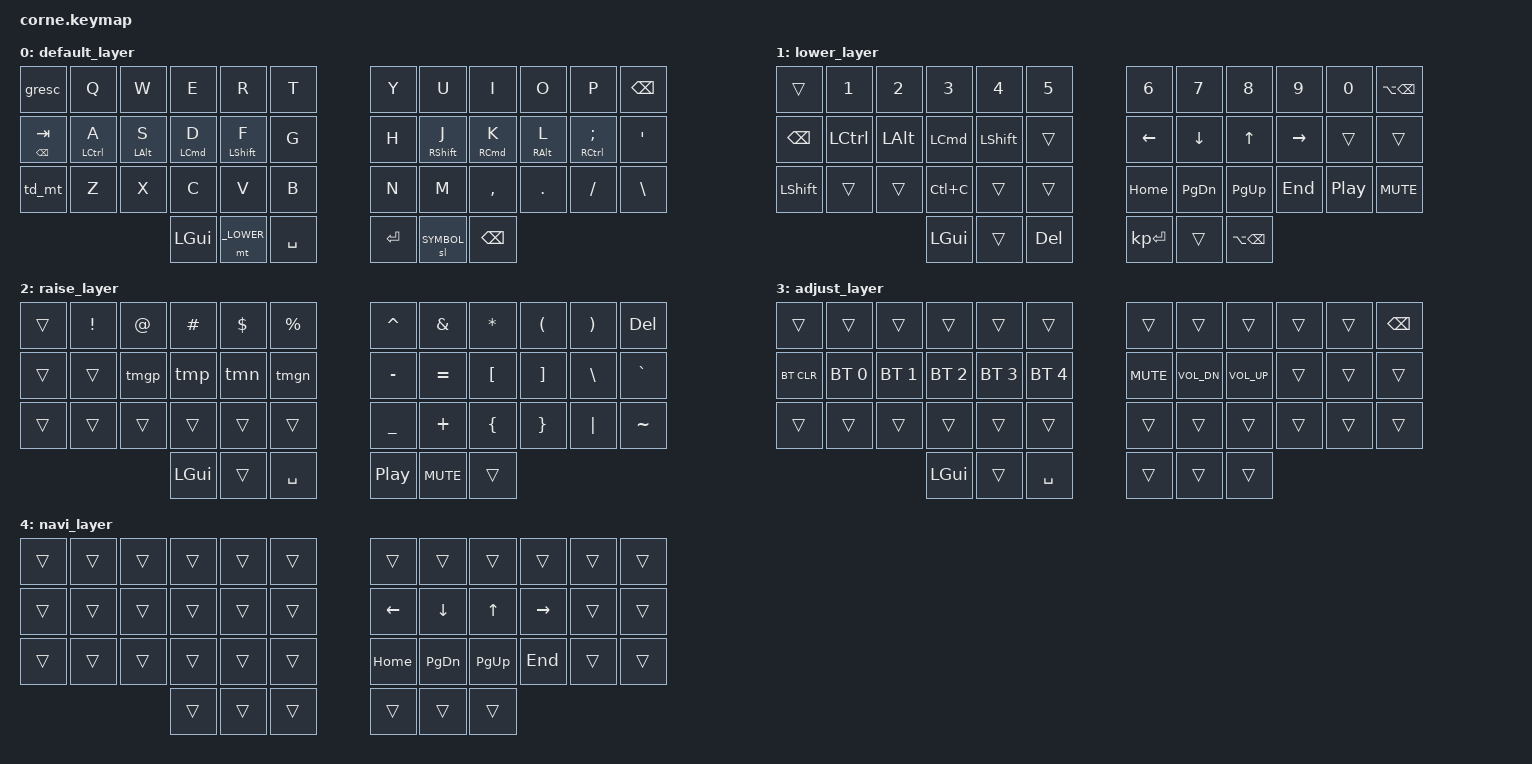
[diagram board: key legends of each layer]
#include <behaviors.dtsi>
#include <dt-bindings/zmk/keys.h>
#include <dt-bindings/zmk/bt.h>
#include <dt-bindings/zmk/ext_power.h>

/* Key index
 0  1  2  3  4  5    6  7  8  9 10 11
12 13 14 15 16 17   18 19 20 21 22 23
24 25 26 27 28 29   30 31 32 33 34 35
         36 37 38   39 40 41     */

#define _DEFAULT 0
#define _LOWER  1
#define _SYMBOL  2
#define _ADJUST  3
#define _NAVI    4

/ {
        behaviors {
                hm: homerow_mods {
                        compatible = "zmk,behavior-hold-tap";
                        #binding-cells = <2>;
                        tapping-term-ms = <180>;
                        quick-tap-ms = <0>;
                        flavor = "tap-preferred";
                        bindings = <&kp>, <&kp>;
                };

                bhm: balanced_homerow_mods {
                        compatible = "zmk,behavior-hold-tap";
                        #binding-cells = <2>;
                        tapping-term-ms = <250>;
                        quick-tap-ms = <125>;
                        flavor = "balanced";
                        bindings = <&kp>, <&kp>;
                };

                qt: quick_tap {
                        compatible = "zmk,behavior-hold-tap";
                        #binding-cells = <2>;
                        flavor = "tap-preferred";
                        tapping-term-ms = <180>;
                        quick-tap-ms = <200>;
                        bindings = <&kp>, <&kp>;
                };

                rh_pht: right_hand_positional_hold_tap {
                        compatible = "zmk,behavior-hold-tap";
                        #binding-cells = <2>;
                        flavor = "tap-unless-interrupted";
                        tapping-term-ms = <100>;   // <---[[produces tap if held longer than tapping-term-ms]]
                        quick-tap-ms = <200>;
                        bindings = <&kp>, <&kp>;
                        hold-trigger-key-positions = <1 2 3 4 5 13 14 15 16 17 25 26 27 28 29>;   // <---[[right-hand keys]]
                };

                td_mt: tap_dance_mod_tap {
                    compatible = "zmk,behavior-tap-dance";
                    #binding-cells = <0>;
                    tapping-term-ms = <200>;
                    bindings = <&mt LSHIFT CAPSLOCK>, <&kp LCTRL>;
                };
        };

        combos {
	        compatible = "zmk,combos";

                // Raise + Space turns on Adjust layer
                combo_adjust {
                        timeout-ms = <50>;
                        key-positions = <37 38>;
                        bindings = <&mo _ADJUST>;
                };
        };

        macros {
                ZMK_MACRO(tmp,
                        bindings
                                = <&macro_press &kp LCTRL>
                                , <&macro_tap &kp B>
                                , <&macro_release &kp LCTRL>
                                , <&macro_tap &kp P>
                        ;
                )
                ZMK_MACRO(tmn,
                        bindings
                                = <&macro_press &kp LCTRL>
                                , <&macro_tap &kp B>
                                , <&macro_release &kp LCTRL>
                                , <&macro_tap &kp N>
                        ;
                )
                ZMK_MACRO(tmgp,
                        bindings
                                = <&macro_press &kp LCTRL>
                                , <&macro_tap &kp G>
                                , <&macro_release &kp LCTRL>
                                , <&macro_tap &kp P>
                        ;
                )
                ZMK_MACRO(tmgn,
                        bindings
                                = <&macro_press &kp LCTRL>
                                , <&macro_tap &kp G>
                                , <&macro_release &kp LCTRL>
                                , <&macro_tap &kp N>
                        ;
                )
        };

        keymap {
                compatible = "zmk,keymap";

                default_layer {
                        bindings = <
   &gresc       &kp Q        &kp W       &kp E        &kp R        &kp T            &kp Y   &kp U        &kp I        &kp O        &kp P            &kp BSPC
   &qt BSPC TAB &hm LCTRL A  &hm LALT S  &hm LCMD D   &hm LSHFT F  &kp G            &kp H   &bhm RSHFT J &bhm RCMD K  &bhm RALT L  &bhm RCTRL SEMI  &kp SQT
   &td_mt       &kp Z        &kp X       &kp C        &kp V        &kp B            &kp N   &kp M        &kp COMMA    &kp DOT      &kp FSLH         &kp BSLH
                                         &kp LGUI     &mt _LOWER   &kp SPACE        &kp RET &sl _SYMBOL  &kp BSPC
                        >;
                };

                lower_layer {
                        bindings = <
   &trans     &kp N1    &kp N2   &kp N3    &kp N4    &kp N5         &kp N6       &kp N7       &kp N8       &kp N9    &kp N0   &kp LA(BSPC)
   &kp BSPC   &kp LCTRL &kp LALT &kp LCMD  &kp LSHFT &trans         &kp LEFT     &kp DOWN     &kp UP       &kp RIGHT &trans   &trans
   &kp LSHFT  &trans    &trans   &kp LC(C) &trans    &trans         &kp HOME     &kp PG_DN    &kp PG_UP    &kp END   &kp C_PP &kp C_MUTE
                                 &kp LGUI  &trans    &kp DEL        &kp KP_ENTER &trans       &kp LA(BSPC)
                        >;
                };

                raise_layer {
                        bindings = <
   &trans &kp EXCL &kp AT &kp HASH &kp DLLR &kp PRCNT     &kp CARET  &kp AMPS   &kp STAR &kp LPAR &kp RPAR &kp DEL 
   &trans &trans   &tmgp  &tmp     &tmn      &tmgn        &kp MINUS  &kp EQUAL  &kp LBKT &kp RBKT &kp BSLH &kp GRAVE
   &trans &trans   &trans &trans   &trans   &trans        &kp UNDER  &kp PLUS   &kp LBRC &kp RBRC &kp PIPE &kp TILDE
                    	  &kp LGUI &trans   &kp SPACE     &kp C_PP   &kp C_MUTE &trans
                        >;
                };

                adjust_layer {
                        bindings = <
   &trans     &trans       &trans       &trans       &trans       &trans           &trans     &trans       &trans       &trans &trans &kp BSPC
   &bt BT_CLR &bt BT_SEL 0 &bt BT_SEL 1 &bt BT_SEL 2 &bt BT_SEL 3 &bt BT_SEL 4     &kp C_MUTE &kp C_VOL_DN &kp C_VOL_UP &trans &trans &trans
   &trans     &trans       &trans       &trans       &trans       &trans           &trans     &trans       &trans       &trans &trans &trans
                          	        &kp LGUI     &trans       &kp SPACE        &trans     &trans       &trans
                        >;
                };

                navi_layer {
                        bindings = <
   &trans  &trans   &trans  &trans   &trans   &trans          &trans   &trans    &trans    &trans    &trans  &trans
   &trans  &trans   &trans  &trans   &trans   &trans          &kp LEFT &kp DOWN  &kp UP    &kp RIGHT &trans  &trans
   &trans  &trans   &trans  &trans   &trans   &trans          &kp HOME &kp PG_DN &kp PG_UP &kp END   &trans  &trans 
                            &trans   &trans   &trans          &trans   &trans    &trans
                        >;
                };
        };
};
